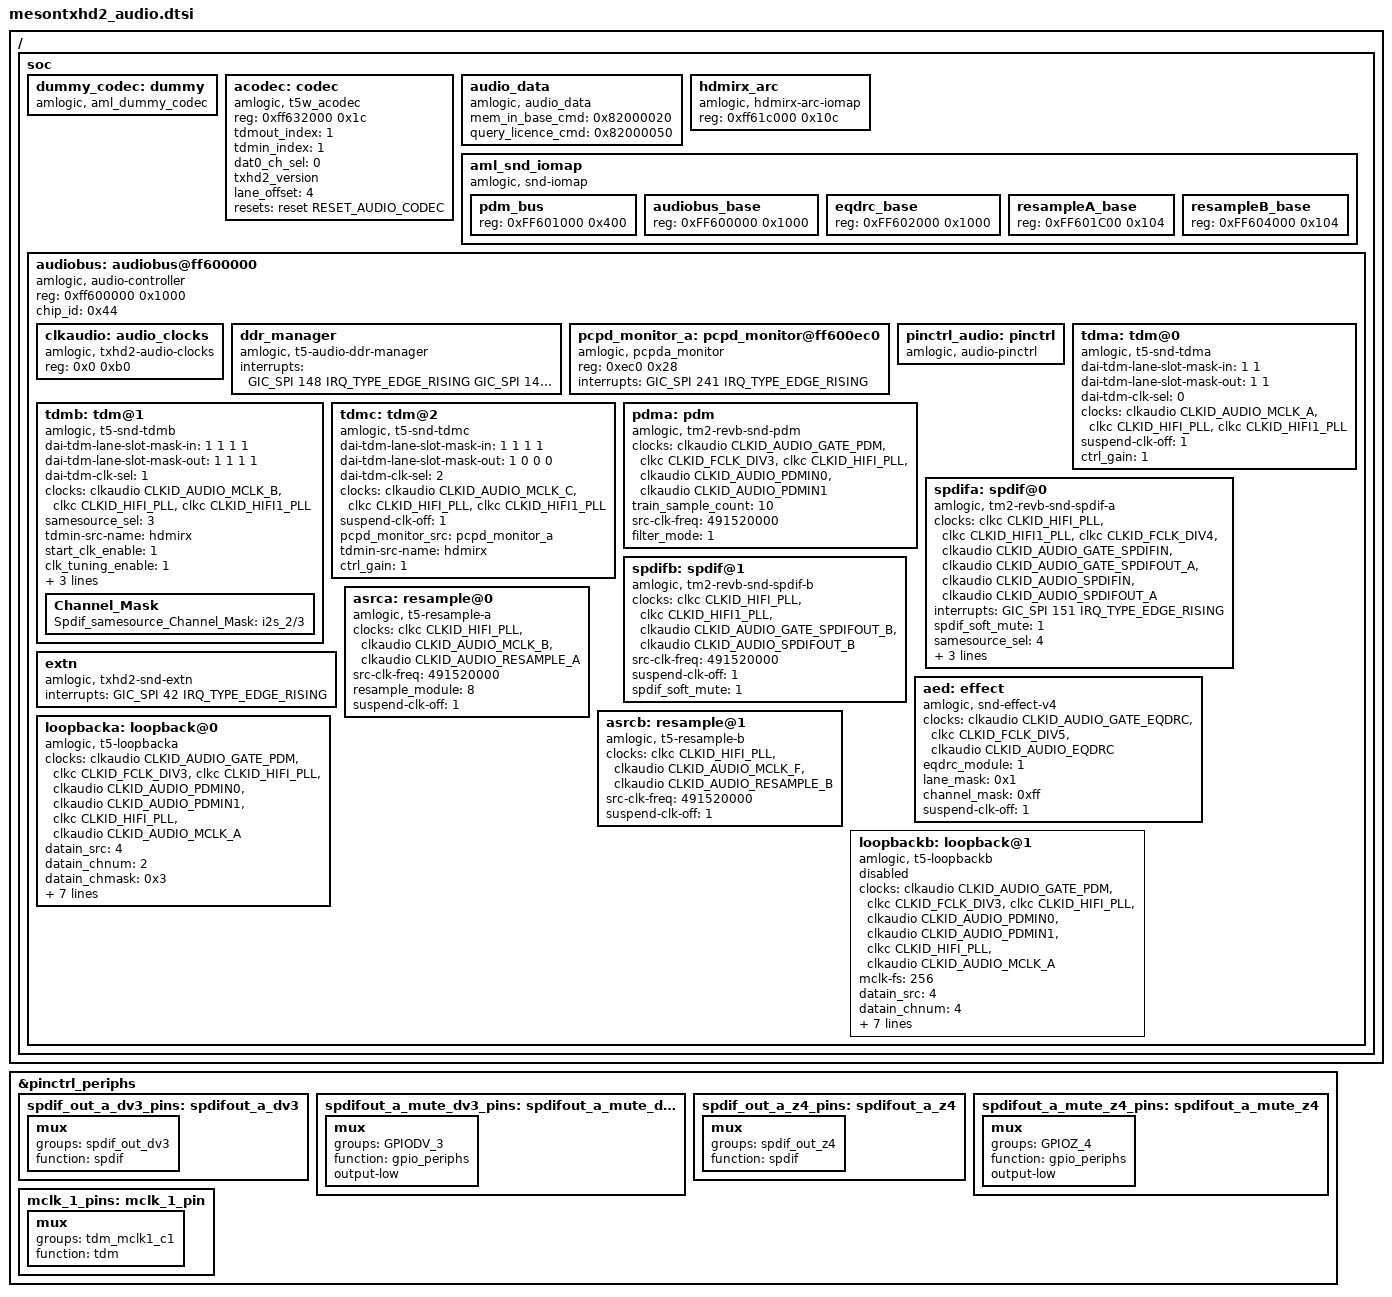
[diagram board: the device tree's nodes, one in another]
// SPDX-License-Identifier: (GPL-2.0+ OR MIT)
/*
 * Copyright (c) 2019 Amlogic, Inc. All rights reserved.
 */

#include "mesontxhd2.dtsi"
#include <dt-bindings/clock/amlogic,txhd2-audio-clk.h>
/ {
	soc {
		dummy_codec:dummy{
			#sound-dai-cells = <0>;
			compatible = "amlogic, aml_dummy_codec";
			status = "okay";
		};
		acodec:codec {
			#sound-dai-cells = <0>;
			compatible = "amlogic, t5w_acodec";
			reg = <0xff632000 0x1c>;
			tdmout_index = <1>;
			tdmin_index = <1>;
			dat0_ch_sel = <0>;
			txhd2_version;
			lane_offset = <4>;
			reset-names = "acodec";
			resets = <&reset RESET_AUDIO_CODEC>;
			status = "okay";
		};

		audio_data: audio_data {
			compatible = "amlogic, audio_data";
			mem_in_base_cmd = <0x82000020>;
			query_licence_cmd = <0x82000050>;
			status = "okay";
		};

		//hdmirx arc
		hdmirx_arc {
			compatible = "amlogic, hdmirx-arc-iomap";
			reg = <0xff61c000 0x10c>;
			#address-cells = <1>;
			#size-cells = <1>;
			ranges = <0x0 0xff61c000 0x10c>;
			reg-names = "hdmirx-arc";
		};
		/* Sound iomap */
		aml_snd_iomap {
			compatible = "amlogic, snd-iomap";
			status = "okay";
			#address-cells=<1>;
			#size-cells=<1>;
			ranges;
			pdm_bus {
				reg = <0xFF601000 0x400>;
			};
			audiobus_base {
				reg = <0xFF600000 0x1000>;
			};
			eqdrc_base {
				reg = <0xFF602000 0x1000>;
			};
			resampleA_base {
				reg = <0xFF601C00 0x104>;
			};
			resampleB_base {
				reg = <0xFF604000 0x104>;
			};
		};
		audiobus: audiobus@ff600000 {
			compatible = "amlogic, audio-controller", "simple-bus";
			reg = <0xff600000 0x1000>;
			reg-names = "audio_bus";
			#address-cells = <1>;
			#size-cells = <1>;
			ranges = <0x0 0xff600000 0x1000>;
			chip_id = <0x44>;
		//	power-domains = <&pwrdm PDID_T7_AUDIO>;
			status = "okay";

			clkaudio: audio_clocks {
				compatible = "amlogic, txhd2-audio-clocks";
				#clock-cells = <1>;
				reg = <0x0 0xb0>;
				status = "okay";
			};
			ddr_manager {
				compatible =
					"amlogic, t5-audio-ddr-manager";
				interrupts = <
					GIC_SPI 148 IRQ_TYPE_EDGE_RISING
					GIC_SPI 149 IRQ_TYPE_EDGE_RISING
					GIC_SPI 150 IRQ_TYPE_EDGE_RISING
					GIC_SPI 48 IRQ_TYPE_EDGE_RISING
					GIC_SPI 152 IRQ_TYPE_EDGE_RISING
					GIC_SPI 153 IRQ_TYPE_EDGE_RISING
					GIC_SPI 154 IRQ_TYPE_EDGE_RISING
					GIC_SPI 49 IRQ_TYPE_EDGE_RISING
				>;
				interrupt-names =
					"toddr_a", "toddr_b", "toddr_c",
					"toddr_d",
					"frddr_a", "frddr_b", "frddr_c",
					"frddr_d";
			};
			pcpd_monitor_a: pcpd_monitor@ff600ec0 {
				compatible = "amlogic, pcpda_monitor";
				/*regbase:0xFE600000 + 0x2e0 << 2*/
				/*size 0x28 byte*/
				reg =<0xec0 0x28>;
				reg-names = "pcpd_reg";
				interrupts = <GIC_SPI 241
					IRQ_TYPE_EDGE_RISING>;
				interrupt-names = "irq_pcpd";
				status = "okay";
			};
			pinctrl_audio: pinctrl {
				compatible = "amlogic, audio-pinctrl";
				status = "okay";
			};
		};/* end of audiobus*/
	};/*end soc*/
};

&audiobus {
	tdma:tdm@0 {
		compatible = "amlogic, t5-snd-tdma";
		#sound-dai-cells = <0>;

		dai-tdm-lane-slot-mask-in = <1 1>;
		dai-tdm-lane-slot-mask-out = <1 1>;
		dai-tdm-clk-sel = <0>;
		clocks = <&clkaudio CLKID_AUDIO_MCLK_A
				&clkc CLKID_HIFI_PLL
				&clkc CLKID_HIFI1_PLL>;
		clock-names = "mclk", "clk_srcpll", "clk_src_cd";
		suspend-clk-off = <1>;
		/* enable control gain */
		ctrl_gain = <1>;
		status = "okay";
	};

	tdmb:tdm@1 {
		compatible = "amlogic, t5-snd-tdmb";
		#sound-dai-cells = <0>;

		dai-tdm-lane-slot-mask-in = <1 1 1 1>;
		dai-tdm-lane-slot-mask-out = <1 1 1 1>;
		dai-tdm-clk-sel = <1>;

		clocks = <&clkaudio CLKID_AUDIO_MCLK_B
				&clkc CLKID_HIFI_PLL
				&clkc CLKID_HIFI1_PLL>;
		clock-names = "mclk", "clk_srcpll", "clk_src_cd";
		/*
		 * 0: tdmout_a;
		 * 1: tdmout_b;
		 * 2: tdmout_c;
		 * 3: spdifout;
		 * 4: spdifout_b;
		 */
		samesource_sel = <3>;
		/* In for ACODEC_ADC */
		/* tdmin-src-name = "acodec_adc"; */
		tdmin-src-name = "hdmirx";
		/*enable default mclk(12.288M), before extern codec start*/
		start_clk_enable = <1>;

		/*tdm clk tuning enable*/
		clk_tuning_enable = <1>;

		/* enable control gain */
		ctrl_gain = <1>;
		suspend-clk-off = <1>;

		status = "okay";
		src-clk-freq = <491520000>;
		/* !!!For --TV platform-- ONLY */
		Channel_Mask {
			/*i2s has 4 pins, 8channel, mux output*/
			Spdif_samesource_Channel_Mask = "i2s_2/3";
		};
	};

	tdmc:tdm@2 {
		compatible = "amlogic, t5-snd-tdmc";
		#sound-dai-cells = <0>;

		dai-tdm-lane-slot-mask-in = <1 1 1 1>;
		dai-tdm-lane-slot-mask-out = <1 0 0 0>;
		dai-tdm-clk-sel = <2>;

		clocks = <&clkaudio CLKID_AUDIO_MCLK_C
				&clkc CLKID_HIFI_PLL
				&clkc CLKID_HIFI1_PLL>;
		clock-names = "mclk", "clk_srcpll", "clk_src_cd";
		suspend-clk-off = <1>;

		/* pcpd_monitor*/
		pcpd_monitor_src = <&pcpd_monitor_a>;

		/* enable control gain */
		tdmin-src-name = "hdmirx";
		ctrl_gain = <1>;
		status = "okay";
	};

	pdma:pdm {
		compatible = "amlogic, tm2-revb-snd-pdm";
		#sound-dai-cells = <0>;

		clocks = <&clkaudio CLKID_AUDIO_GATE_PDM
			&clkc CLKID_FCLK_DIV3
			&clkc CLKID_HIFI_PLL
			&clkaudio CLKID_AUDIO_PDMIN0
			&clkaudio CLKID_AUDIO_PDMIN1>;
		clock-names = "gate",
			"sysclk_srcpll",
			"dclk_srcpll",
			"pdm_dclk",
			"pdm_sysclk";

		train_sample_count = <10>;
		src-clk-freq = <491520000>;
		/* mode 0~4, defalut:1 */
		filter_mode = <1>;

		status = "okay";
	};

	spdifa:spdif@0 {
		compatible = "amlogic, tm2-revb-snd-spdif-a";
		#sound-dai-cells = <0>;

		clocks = <&clkc CLKID_HIFI_PLL
				&clkc CLKID_HIFI1_PLL
				&clkc CLKID_FCLK_DIV4
				&clkaudio CLKID_AUDIO_GATE_SPDIFIN
				&clkaudio CLKID_AUDIO_GATE_SPDIFOUT_A
				&clkaudio CLKID_AUDIO_SPDIFIN
				&clkaudio CLKID_AUDIO_SPDIFOUT_A>;
		clock-names = "sysclk", "clk_src_cd", "fixed_clk", "gate_spdifin",
				"gate_spdifout", "clk_spdifin", "clk_spdifout";

		interrupts =
				<GIC_SPI 151 IRQ_TYPE_EDGE_RISING>;
		interrupt-names = "irq_spdifin";
		/*
		 * 0: tdmout_a;
		 * 1: tdmout_b;
		 * 2: tdmout_c;
		 * 3: spdifout;
		 * 4: spdifout_b;
		 * 5: earc;
		 */
		spdif_soft_mute = <1>;
		samesource_sel = <4>;
		src-clk-freq = <491520000>;
		/*spdif clk tuning enable*/
		clk_tuning_enable = <1>;
		suspend-clk-off = <1>;
		status = "okay";
	};

	spdifb:spdif@1 {
		compatible = "amlogic, tm2-revb-snd-spdif-b";
		#sound-dai-cells = <0>;

		clocks = <&clkc CLKID_HIFI_PLL /*CLKID_HIFI_PLL*/
				&clkc CLKID_HIFI1_PLL
				&clkaudio CLKID_AUDIO_GATE_SPDIFOUT_B
				&clkaudio CLKID_AUDIO_SPDIFOUT_B>;
		clock-names = "sysclk", "clk_src_cd",
				"gate_spdifout", "clk_spdifout";
		src-clk-freq = <491520000>;
		suspend-clk-off = <1>;
		spdif_soft_mute = <1>;
		status = "okay";
	};

	extn:extn {
		compatible = "amlogic, txhd2-snd-extn";
		#sound-dai-cells = <0>;

		interrupts =
				<GIC_SPI 42 IRQ_TYPE_EDGE_RISING>;
		interrupt-names = "irq_frhdmirx";

		status = "okay";
	};

	aed:effect {
		compatible = "amlogic, snd-effect-v4";
		#sound-dai-cells = <0>;

		clocks = <&clkaudio CLKID_AUDIO_GATE_EQDRC
			&clkc CLKID_FCLK_DIV5
			&clkaudio CLKID_AUDIO_EQDRC>;
		clock-names = "gate", "srcpll", "eqdrc";

		/*
		 * 0:tdmout_a
		 * 1:tdmout_b
		 * 2:tdmout_c
		 * 3:spdifout
		 * 4:spdifout_b
		 */
		eqdrc_module = <1>;
		/* max 0xf, each bit for one lane, usually one lane */
		lane_mask = <0x1>;
		/* max 0xff, each bit for one channel */
		channel_mask = <0xff>;
		suspend-clk-off = <1>;
		status = "okay";
	};

	asrca: resample@0 {
		compatible = "amlogic, t5-resample-a";
		clocks = <&clkc CLKID_HIFI_PLL
			&clkaudio CLKID_AUDIO_MCLK_B
			&clkaudio CLKID_AUDIO_RESAMPLE_A>;
		clock-names = "resample_pll", "resample_src", "resample_clk";

		/*same with toddr_src
		 *	TDMIN_A,    0
		 *	TDMIN_B,    1
		 *	TDMIN_C,    2
		 *	SPDIFIN,    3
		 *	PDMIN,      4
		 *	FRATV,      5
		 *	TDMIN_LB,   6
		 *	LOOPBACK_A, 7
		 *	FRHDMIRX,   8
		 *	LOOPBACK_B, 9
		 *	SPDIFIN_LB, 10
		 *	EARC_RX,    11
		 */
		src-clk-freq = <491520000>;
		resample_module = <8>;
		suspend-clk-off = <1>;
		status = "okay";
	};

	asrcb: resample@1 {
		compatible = "amlogic, t5-resample-b";
		clocks = <&clkc CLKID_HIFI_PLL
			&clkaudio CLKID_AUDIO_MCLK_F
			&clkaudio CLKID_AUDIO_RESAMPLE_B>;
		clock-names = "resample_pll", "resample_src", "resample_clk";
		src-clk-freq = <491520000>;
		/*this resample is only used for loopback_A.*/
		suspend-clk-off = <1>;
		status = "okay";
	};
	loopbacka:loopback@0 {
		compatible = "amlogic, t5-loopbacka";
		#sound-dai-cells = <0>;

		clocks = <&clkaudio CLKID_AUDIO_GATE_PDM
			&clkc CLKID_FCLK_DIV3
			&clkc CLKID_HIFI_PLL
			&clkaudio CLKID_AUDIO_PDMIN0
			&clkaudio CLKID_AUDIO_PDMIN1
			&clkc CLKID_HIFI_PLL
			&clkaudio CLKID_AUDIO_MCLK_A>;
		clock-names = "pdm_gate",
			"pdm_sysclk_srcpll",
			"pdm_dclk_srcpll",
			"pdm_dclk",
			"pdm_sysclk",
			"tdminlb_mpll",
			"tdminlb_mclk";

		/* datain src
		 * 0: tdmin_a;
		 * 1: tdmin_b;
		 * 2: tdmin_c;
		 * 3: spdifin;
		 * 4: pdmin;
		 */
		datain_src = <4>;
		datain_chnum = <2>;
		datain_chmask = <0x3>;
		/* config which data pin for loopback */
		datain-lane-mask-in = <1 1 0 0>;

		/* calc mclk for datalb */
		mclk-fs = <256>;
		/* tdmin_lb src
		 * 0: tdmoutA
		 * 1: tdmoutB
		 * 2: tdmoutC
		 * 3: PAD_TDMINA_DIN*, refer to core pinmux
		 * 4: PAD_TDMINB_DIN*, refer to core pinmux
		 * 5: PAD_TDMINC_DIN*, refer to core pinmux
		 * 6: PAD_TDMINA_D*, oe, refer to core pinmux
		 * 7: PAD_TDMINB_D*, oe, refer to core pinmux
		 */
		/* if tdmin_lb >= 3, use external loopback */
		datalb_src = <1>;
		datalb_chnum = <2>;
		datalb_chmask = <0x3>;
		/* config which data pin as loopback */
		datalb-lane-mask-in = <1 0 0 0>;

		/* define loopack with pdm mic. */
		mic-src = <&pdma>;
		status = "okay";
	};

	loopbackb:loopback@1 {
		compatible = "amlogic, t5-loopbackb";
		#sound-dai-cells = <0>;

		clocks = <&clkaudio CLKID_AUDIO_GATE_PDM
			&clkc CLKID_FCLK_DIV3
			&clkc CLKID_HIFI_PLL
			&clkaudio CLKID_AUDIO_PDMIN0
			&clkaudio CLKID_AUDIO_PDMIN1
			&clkc CLKID_HIFI_PLL
			&clkaudio CLKID_AUDIO_MCLK_A>;
		clock-names = "pdm_gate",
			"pdm_sysclk_srcpll",
			"pdm_dclk_srcpll",
			"pdm_dclk",
			"pdm_sysclk",
			"tdminlb_mpll",
			"tdminlb_mclk";

		/* calc mclk for datain_lb */
		mclk-fs = <256>;

		/* datain src
		 * 0: tdmin_a;
		 * 1: tdmin_b;
		 * 2: tdmin_c;
		 * 3: spdifin;
		 * 4: pdmin;
		 */
		datain_src = <4>;
		datain_chnum = <4>;
		datain_chmask = <0xf>;
		/* config which data pin for loopback */
		datain-lane-mask-in = <1 0 1 0>;

		/* tdmin_lb src
		 * 0: tdmoutA
		 * 1: tdmoutB
		 * 2: tdmoutC
		 * 3: PAD_TDMINA_DIN*, refer to core pinmux
		 * 4: PAD_TDMINB_DIN*, refer to core pinmux
		 * 5: PAD_TDMINC_DIN*, refer to core pinmux
		 * 6: PAD_TDMINA_D*, oe, refer to core pinmux
		 * 7: PAD_TDMINB_D*, oe, refer to core pinmux
		 */
		/* if tdmin_lb >= 3, use external loopback */
		datalb_src = <1>;
		datalb_chnum = <2>;
		datalb_chmask = <0x3>;
		/* config which data pin as loopback */
		datalb-lane-mask-in = <1 0 0 0>;
		suspend-clk-off = <1>;
		status = "disabled";
	};
}; /* end of audiobus */

&pinctrl_periphs {
	spdif_out_a_dv3_pins: spdifout_a_dv3 {
		mux { /* GPIODV_3 */
			groups = "spdif_out_dv3";
			function = "spdif";
		};
	};

	spdifout_a_mute_dv3_pins: spdifout_a_mute_dv3 {
		mux { /* GPIODV_3*/
			groups = "GPIODV_3";
			function = "gpio_periphs";
			output-low;
		};
	};

	spdif_out_a_z4_pins: spdifout_a_z4 {
		mux { /* GPIOZ_4 */
			groups = "spdif_out_z4";
			function = "spdif";
		};
	};

	spdifout_a_mute_z4_pins: spdifout_a_mute_z4 {
		mux { /* GPIOZ_4*/
			groups = "GPIOZ_4";
			function = "gpio_periphs";
			output-low;
		};
	};

	mclk_1_pins: mclk_1_pin {
		mux { /* GPIOC_1 */
			groups = "tdm_mclk1_c1";
			function = "tdm";
		};
	};
};
